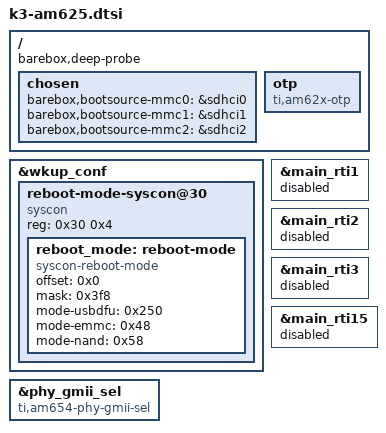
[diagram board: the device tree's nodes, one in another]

/ {
	barebox,deep-probe;

	chosen {
		barebox,bootsource-mmc0 = &sdhci0;
		barebox,bootsource-mmc1 = &sdhci1;
		barebox,bootsource-mmc2 = &sdhci2;
	};

	otp: otp {
		compatible = "ti,am62x-otp";
	};
};

&wkup_conf {
	reboot-mode-syscon@30 {
		compatible = "syscon", "simple-mfd";
		reg = <0x30 0x4>;

		reboot_mode: reboot-mode {
			compatible = "syscon-reboot-mode";
			offset = <0x0>;
			mask = <0x3f8>;
			mode-usbdfu = <0x250>;
			mode-emmc = <0x48>;
			mode-nand = <0x58>;
		};
	};
};

&phy_gmii_sel {
	compatible = "ti,am654-phy-gmii-sel", "syscon";
};

&main_rti1 {
	status = "disabled";
};

&main_rti2 {
	status = "disabled";
};

&main_rti3 {
	status = "disabled";
};

&main_rti15 {
	status = "disabled";
};
